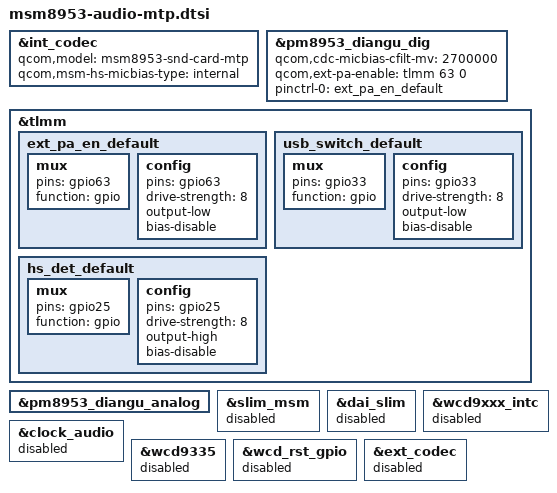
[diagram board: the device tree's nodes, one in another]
/*
 * Copyright (c) 2015-2016, The Linux Foundation. All rights reserved.
 *
 * This program is free software; you can redistribute it and/or modify
 * it under the terms of the GNU General Public License version 2 and
 * only version 2 as published by the Free Software Foundation.
 *
 * This program is distributed in the hope that it will be useful,
 * but WITHOUT ANY WARRANTY; without even the implied warranty of
 * MERCHANTABILITY or FITNESS FOR A PARTICULAR PURPOSE.  See the
 * GNU General Public License for more details.
 */

&int_codec {
	status = "okay";
	qcom,model = "msm8953-snd-card-mtp";
	qcom,msm-hs-micbias-type = "internal";
};

&pm8953_diangu_dig {
	status = "okay";
	qcom,cdc-micbias-cfilt-mv = <2700000>; /* set micbias2 to 2.7v default */
	qcom,ext-pa-enable = <&tlmm 63  0>;
	pinctrl-names = "default";
	pinctrl-0 = <&ext_pa_en_default>;
};
&tlmm {
	ext_pa_en_default: ext_pa_en_default {
		mux {
			pins = "gpio63";
			function = "gpio";
		};

		config {
			pins = "gpio63";
			drive-strength = <8>;
			output-low;
			bias-disable;
		};
	};

};

&pm8953_diangu_analog {
	status = "okay";
};
// ontim:houzn add
&tlmm{
	usb_switch_default: usb_switch_default{
		mux {
			pins = "gpio33";
			function = "gpio";
		};

		config {
			pins = "gpio33";
			drive-strength = <8>;
			output-low; // select usb default
			bias-disable;
		};
	};

	hs_det_default: hs_det_default{
		mux {
			pins = "gpio25";
			function = "gpio";
		};

		config {
			pins = "gpio25";
			drive-strength = <8>;
			output-high;
			bias-disable;
		};
	};
};
// add end
&slim_msm {
	status = "disabled";
};

&dai_slim {
	status = "disabled";
};

&wcd9xxx_intc {
	status = "disabled";
};

&clock_audio {
	status = "disabled";
};

&wcd9335 {
	status = "disabled";
};

&wcd_rst_gpio {
	status = "disabled";
};

&ext_codec {
	status = "disabled";
};
